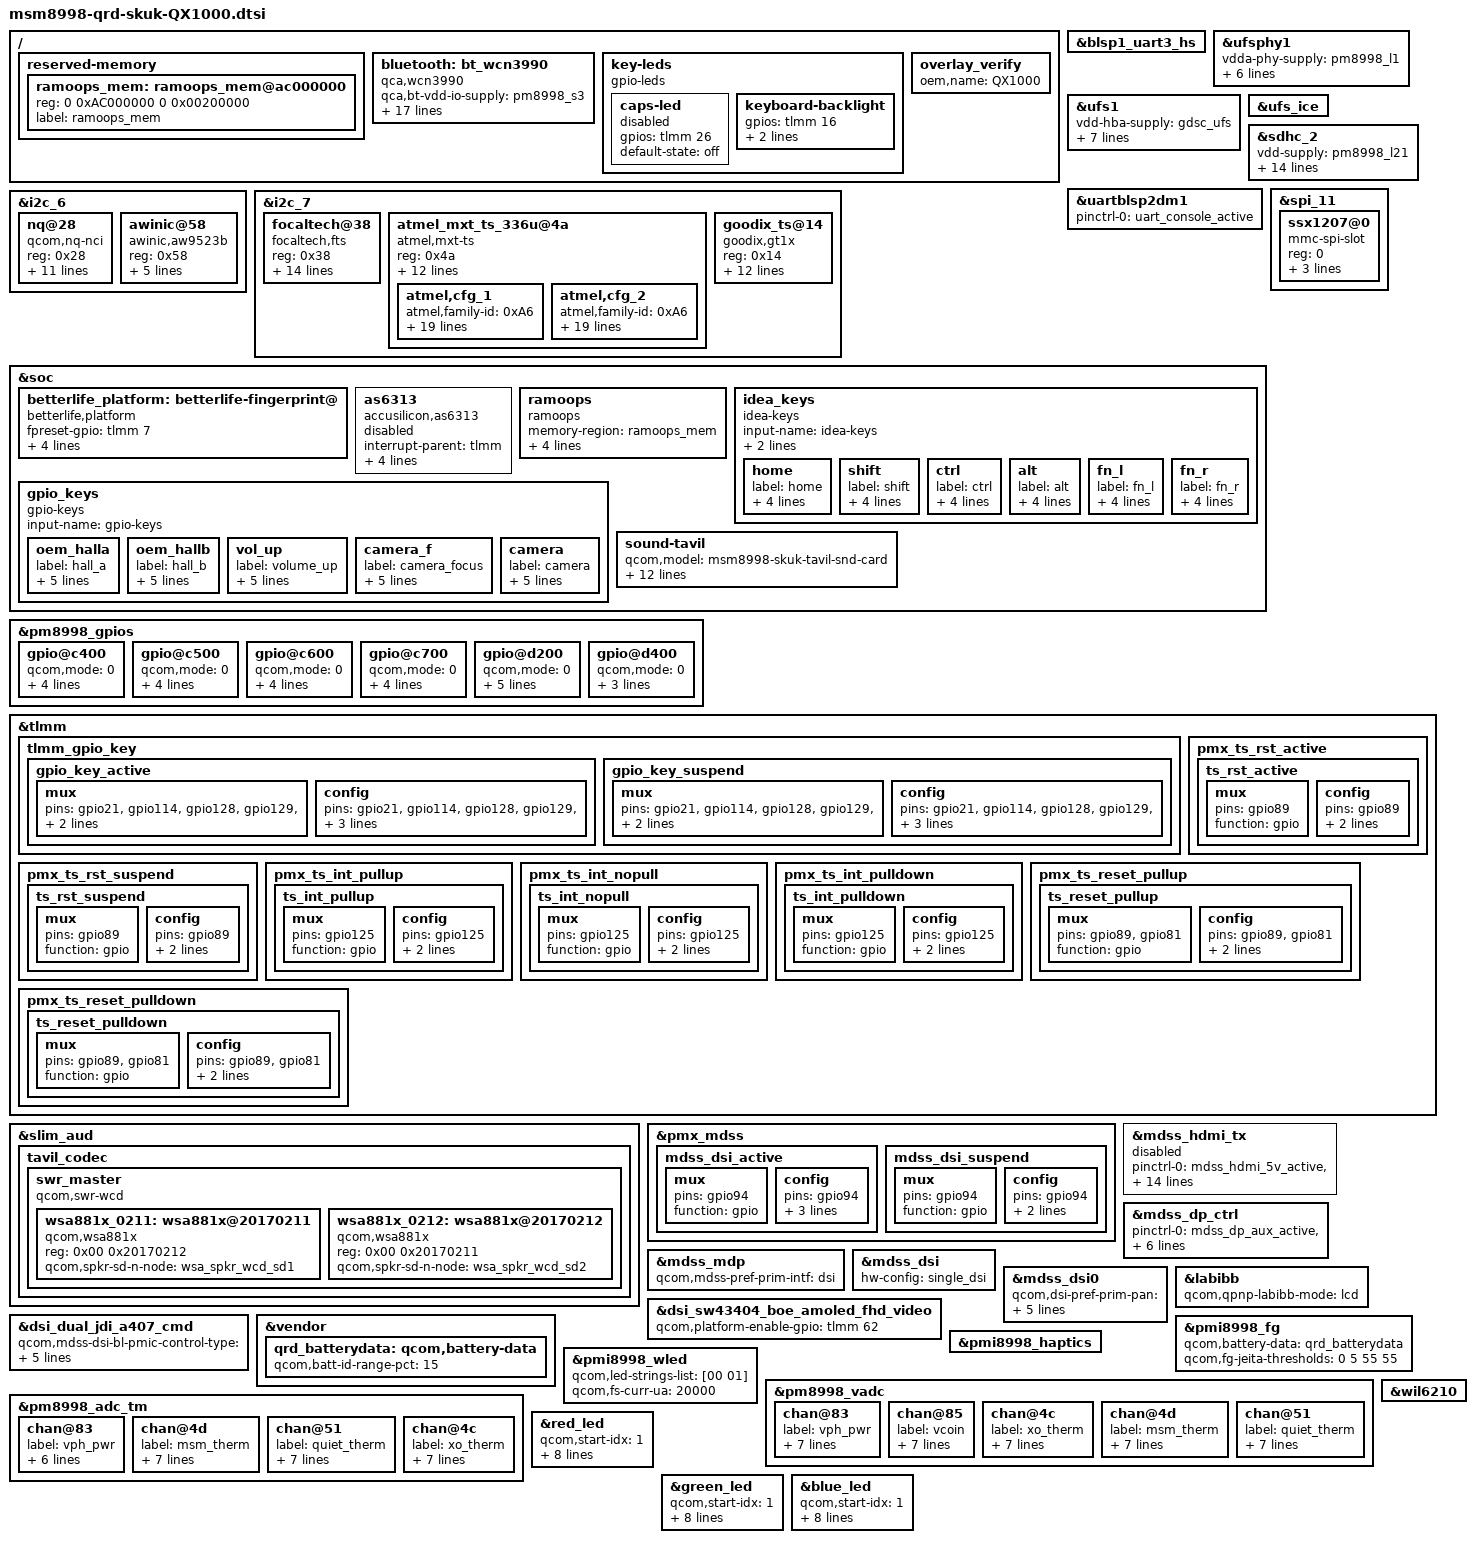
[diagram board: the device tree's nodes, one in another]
/* Copyright (c) 2016-2017, The Linux Foundation. All rights reserved.
 *
 * This program is free software; you can redistribute it and/or modify
 * it under the terms of the GNU General Public License version 2 and
 * only version 2 as published by the Free Software Foundation.
 *
 * This program is distributed in the hope that it will be useful,
 * but WITHOUT ANY WARRANTY; without even the implied warranty of
 * MERCHANTABILITY or FITNESS FOR A PARTICULAR PURPOSE.  See the
 * GNU General Public License for more details.
 */

#include <dt-bindings/interrupt-controller/irq.h>
#include "msm8998-pinctrl.dtsi"
#include "msm8998-audio.dtsi"

/ {
	reserved-memory {
		ramoops_mem: ramoops_mem@ac000000 {
			reg = <0 0xAC000000 0 0x00200000>;
			label = "ramoops_mem";
		};
	};
};

/ {
	bluetooth: bt_wcn3990 {
		compatible = "qca,wcn3990";
		qca,bt-vdd-io-supply = <&pm8998_s3>;
		qca,bt-vdd-xtal-supply = <&pm8998_s5>;
		qca,bt-vdd-core-supply = <&pm8998_l7>;
		qca,bt-vdd-pa-supply = <&pm8998_l17>;
		qca,bt-vdd-ldo-supply = <&pm8998_l25>;
		qca,bt-chip-pwd-supply = <&pmi8998_bob_pin1>;
		clocks = <&clock_gcc clk_rf_clk2_pin>;
		clock-names = "rf_clk2";

		qca,bt-vdd-io-voltage-level = <1352000 1352000>;
		qca,bt-vdd-xtal-voltage-level = <2040000 2040000>;
		qca,bt-vdd-core-voltage-level = <1800000 1800000>;
		qca,bt-vdd-pa-voltage-level = <1304000 1304000>;
		qca,bt-vdd-ldo-voltage-level = <3312000 3312000>;
		qca,bt-chip-pwd-voltage-level = <3600000 3600000>;

		qca,bt-vdd-io-current-level = <1>; /* LPM/PFM */
		qca,bt-vdd-xtal-current-level = <1>; /* LPM/PFM */
		qca,bt-vdd-core-current-level = <1>; /* LPM/PFM */
		qca,bt-vdd-pa-current-level = <1>; /* LPM/PFM */
		qca,bt-vdd-ldo-current-level = <1>; /* LPM/PFM */
	};

	key-leds{
		compatible = "gpio-leds";
		caps-led {
			gpios = <&tlmm 26 0x00>;
			default-state = "off";
			status = "disable";

		};
		keyboard-backlight {
			gpios = <&tlmm 16 0x00>;
			default-state = "off";
			retain-state-suspended;
		};
	};
};

&blsp1_uart3_hs {
	status = "ok";
};

&ufsphy1 {
	vdda-phy-supply = <&pm8998_l1>;
	vdda-pll-supply = <&pm8998_l2>;
	vddp-ref-clk-supply = <&pm8998_l26>;
	vdda-phy-max-microamp = <51400>;
	vdda-pll-max-microamp = <14600>;
	vddp-ref-clk-max-microamp = <100>;
	vddp-ref-clk-always-on;
	status = "ok";
};

&ufs1 {
	vdd-hba-supply = <&gdsc_ufs>;
	vdd-hba-fixed-regulator;
	vcc-supply = <&pm8998_l20>;
	vccq-supply = <&pm8998_l26>;
	vccq2-supply = <&pm8998_s4>;
	vcc-max-microamp = <750000>;
	vccq-max-microamp = <560000>;
	vccq2-max-microamp = <750000>;
	status = "ok";
};

&ufs_ice {
	status = "ok";
};

&sdhc_2 {
	vdd-supply = <&pm8998_l21>;
	qcom,vdd-voltage-level = <2950000 2960000>;
	qcom,vdd-current-level = <200 800000>;

	vdd-io-supply = <&pm8998_l13>;
	qcom,vdd-io-voltage-level = <1808000 2960000>;
	qcom,vdd-io-current-level = <200 22000>;

	pinctrl-names = "active", "sleep";
	pinctrl-0 = <&sdc2_clk_on  &sdc2_cmd_on &sdc2_data_on &sdc2_cd_on>;
	pinctrl-1 = <&sdc2_clk_off &sdc2_cmd_off &sdc2_data_off &sdc2_cd_off>;

	qcom,clk-rates = <400000 20000000 25000000
				50000000 100000000 200000000>;
	qcom,bus-speed-mode = "SDR12", "SDR25", "SDR50", "DDR50", "SDR104";

	cd-gpios = <&tlmm 95 0x1>;

	status = "ok";
};

&uartblsp2dm1 {
	status = "ok";
	pinctrl-names = "default";
	pinctrl-0 = <&uart_console_active>;
};

&i2c_6 { /* BLSP1 QUP6 (NFC) */
	status = "okay";
	nq@28 {
		compatible = "qcom,nq-nci";
		reg = <0x28>;
		qcom,nq-irq = <&tlmm 92 0x00>;
		qcom,nq-ven = <&tlmm 12 0x00>;
		qcom,nq-firm = <&tlmm 93 0x00>;
		qcom,nq-clkreq = <&pm8998_gpios 21 0x00>;
		qcom,nq-esepwr = <&tlmm 116 0x00>;
		interrupt-parent = <&tlmm>;
		qcom,clk-src = "BBCLK3";
		interrupts = <92 0>;
		interrupt-names = "nfc_irq";
		pinctrl-names = "nfc_active", "nfc_suspend";
		pinctrl-0 = <&nfc_int_active &nfc_enable_active>;
		pinctrl-1 = <&nfc_int_suspend &nfc_enable_suspend>;
		clocks = <&clock_gcc clk_ln_bb_clk3_pin>;
		clock-names = "ref_clk";
	};

	awinic@58 {
		compatible = "awinic,aw9523b";
		reg = <0x58>;
		interrupt-parent = <&tlmm>;
		interrupts = <50 0x2008>;
		interrupt-names = "kpd_irq";
		awinic,reset-gpio = <&tlmm 51 0>;
		awinic,caps-gpio = <&tlmm 26 0>;
		awinic,irq-gpio = <&tlmm 50 0x2008>;
	};
};
&i2c_7 {
	status = "okay";
	focaltech@38{
		compatible = "focaltech,fts";
		reg = <0x38>;
		interrupt-parent = <&tlmm>;
		interrupts = <125 0x2008>;
		focaltech,reset-gpio = <&tlmm 89 0x00>;
		ysensor-supply = <&pm8998_l21>;
		//focaltech,power-gpio = <&tlmm 77 0x00>;
		focaltech,irq-gpio = <&tlmm 125 0x2008>;
		focaltech,max-touch-number = <5>;
		focaltech,display-coords =  <0 0 1080 2160>;

		//pinctrl-names = "pmx_ts_active","pmx_ts_suspend","pmx_ts_release";
		//pinctrl-0 = <&ts_int_active &ts_reset_active>;
		//pinctrl-1 = <&ts_int_suspend &ts_reset_suspend>;
		//pinctrl-2 = <&ts_release>;

		vcc_i2c-supply = <&pm8998_l6>;
		vdd-supply = <&pm8998_l28>;
		focaltech,have-key;
		focaltech,key-number = <3>;
		focaltech,keys = <139 102 158>;
		focaltech,key-y-coord = <2000>;
		focaltech,key-x-coords = <200 600 800>;
	};
	atmel_mxt_ts_336u@4a {
                   compatible = "atmel,mxt-ts";
                   reg = <0x4a>;
                   interrupt-parent = <&tlmm>;
                   interrupts = <125 0x2008>;
                   vddio-supply = <&pm8998_l6>;
                   vdd-supply = <&pm8998_l28>;
                   /* pins used by touchscreen */
                   //pinctrl-names = "pmx_ts_active","pmx_ts_suspend";
                   //pinctrl-0 = <&ts_int_active &ts_reset_active>;
                   //pinctrl-1 = <&ts_int_suspend &ts_reset_suspend>;
                   atmel,reset-gpio = <&tlmm 89 0x00>;
                   atmel,irq-gpio = <&tlmm 125 0x2008>;
                   atmel,mxt-fw-name = "mXT336U10AA.fw";
                   atmel,config-array-size = <2>;
                   atmel,default-config = <0>;
                   atmel,irqflags = <0x2008>;
                   atmel,vendor-id-byte = /bits/ 8 <0 3>;
                   atmel,cut-off-power = <1>;
                   atmel,cfg_1 {
                            atmel,family-id = <0xA6>;
                            atmel,variant-id = <0x06>;
                            atmel,version = <0x10>;
                            atmel,build = <0xAA>;
                            atmel,rev-id = <0x2>;
                            atmel,mxt-cfg-name = "mxt_336u_biel_hw1_config.fw";
                            atmel,vendor-id = /bits/ 8 <0x31 0x31>; /* Biel HW ver 1 */
                            atmel,key-codes = <158 102 139>;
                            atmel,selfintthr-stylus = <0>;
                            atmel,t71-tchthr-pos = <22>;
                            atmel,self-chgtime-min = <0>;
                            atmel,self-chgtime-max = <0>;
                            atmel,mult-intthr-sensitive = <12>;
                            atmel,mult-intthr-not-sensitive = <17>;
                            atmel,atchthr-sensitive = <6>;
                            atmel,mult-tchthr-sensitive = <0>;
                            atmel,mult-tchthr-not-sensitive = <0>;
                            atmel,wake-up-self-adcx = <16>;
                            atmel,support-wakeup-gesture;
                   };
                   atmel,cfg_2 {
                            atmel,family-id = <0xA6>;
                            atmel,variant-id = <0x06>;
                            atmel,version = <0x10>;
                            atmel,build = <0xAA>;
                            atmel,rev-id = <0x2>;
                            atmel,mxt-cfg-name = "mxt_336u_biel_hw2_config.fw";
                            atmel,vendor-id = /bits/ 8 <0x31 0x32>; /* Biel HW ver 2 */
                            atmel,key-codes = <158 102 139>;
                            atmel,selfintthr-stylus = <0>;
                            atmel,t71-tchthr-pos = <22>;
                            atmel,self-chgtime-min = <0>;
                            atmel,self-chgtime-max = <0>;
                            atmel,mult-intthr-sensitive = <12>;
                            atmel,mult-intthr-not-sensitive = <17>;
                            atmel,atchthr-sensitive = <6>;
                            atmel,mult-tchthr-sensitive = <0>;
                            atmel,mult-tchthr-not-sensitive = <0>;
                            atmel,wake-up-self-adcx = <16>;
                            atmel,support-wakeup-gesture;
                   };
         };

		goodix_ts@14 {
			compatible = "goodix,gt1x";
			reg = <0x14>;
			interrupt-parent = <&tlmm>;
			interrupts = <125 0x2008>;
			vdd_ana-supply = <&pm8998_l28>;
			//vcc_i2c-supply = <&pm8998_l6>;
			goodix,rst-gpio = <&tlmm 89 0x00>;
			goodix,pwr-gpio = <&tlmm 81 0x00>;
			goodix,irq-gpio = <&tlmm 125 0x2008>;
			pinctrl-names = "pmx_ts_wakeup","pmx_ts_normal","pmx_ts_poweroff","pmx_ts_sleep";
			pinctrl-0 = <&ts_int_pullup &ts_reset_pullup>;
			pinctrl-1 = <&ts_int_nopull &ts_reset_pullup>;
			pinctrl-2 = <&ts_int_pulldown &ts_reset_pulldown>;
			pinctrl-3 = <&ts_int_pulldown &ts_reset_pullup>;
			
			goodix,default-config0 = [
			46 38 04 70 08 3A 0C 00 01
			60 00 06 50 3C 33 01 00 0C
			00 00 28 17 1A 1D 08 06 00
			00 00 00 41 44 00 00 00 00
			12 14 00 40 00 00 00 00 00
			00 88 28 20 64 66 10 09 00
			00 38 AE 53 24 44 03 2D 96
			C0 94 02 00 18 04 C8 3E 9F
			50 8A 61 7F 73 00 84 00 00
			00 00 00 00 00 00 00 00 00
			00 00 00 00 00 00 00 00 00
			00 00 00 00 00 00 00 33 00
			00 00 00 00 00 00 06 00 00
			00 00 00 00 00 00 20 00 00
			00 00 00 00 00 00 00 00 00
			00 DF 07 32 1E 05 03 04 00
			02 01 07 06 08 09 0B 0A 0C
			0D 0E 0F 10 11 12 13 14 15
			16 17 18 19 1A 1B 1C 1D 1E
			1F 02 01 03 04 05 06 07 08
			09 0B 0F 0C 0E 0D 0A 18 FF
			FF FF FF FF FF 00 30 00 00
			00 0F F0 00 00 80 00 00 00
			00 00 00 00 00 00 00 00 00
			14 88 34 65 78 00 14 50 6D
			91 14 28 00 54 10 00 00 00
			00 00 9E 28 01];

	};	 
};

&spi_11 {//enable gpio is config in file kernel/msm-4.4/drivers/mmc/host/mmc_spi.c
    ssx1207@0 {
    compatible = "mmc-spi-slot";
    reg = <0>;
    spi-max-frequency = <50000000>;
    spi-cpol;
    spi-cpha;
    //spi-cs-high;
    };
};

&soc {

    betterlife_platform: betterlife-fingerprint@ {
        compatible = "betterlife,platform";
        fpreset-gpio = <&tlmm 7 0>;
        fpint-gpio = <&tlmm 126 0>;
        fppower-gpio = <&tlmm 25 0>;
        //fppower-gpio1v8 = <&tlmm 25 0>;
        interrupt-parent = <&tlmm>;
        interrupts = <126 0x0>;
        status = "okay";
    };
 
    as6313 {
        compatible = "accusilicon,as6313";
        //reg = <0x0d>;
        //vdd-sim-supply = <&pm8994_l9>;
        interrupt-parent = <&tlmm>;
        interrupts = <123 0x2008>; //79
        sck-gpio = <&tlmm 32 0x00>;
        sda-gpio = <&tlmm 33 0x00>;
        irq-gpio = <&tlmm 123 0x2008>;
		status = "disable";
    };

    ramoops {
        compatible = "ramoops";
        status = "ok";
        memory-region = <&ramoops_mem>;
        console-size = <0x0 0x00080000>;
        pmsg-size    = <0x0 0x00040000>;
        record-size  = <0x0 0x00008000>;
        ftrace-size  = <0x0 0x00020000>;
    };
};

&pm8998_gpios {
	/* GPIO 5 for Home Key */
	gpio@c400 {
		status = "okay";
		qcom,mode = <0>;
		qcom,pull = <0>;
		qcom,vin-sel = <0>;
		qcom,src-sel = <0>;
		qcom,out-strength = <1>;
	};

	/* GPIO 6 for Vol+ Key */
	gpio@c500 {
		status = "okay";
		qcom,mode = <0>;
		qcom,pull = <0>;
		qcom,vin-sel = <0>;
		qcom,src-sel = <0>;
		qcom,out-strength = <1>;
	};
	gpio@c600 {
		status = "okay";
		qcom,mode = <0>;
		qcom,pull = <0>;
		qcom,vin-sel = <0>;
		qcom,src-sel = <0>;
		qcom,out-strength = <1>;
	};
	gpio@c700 {
		status = "okay";
		qcom,mode = <0>;
		qcom,pull = <0>;
		qcom,vin-sel = <0>;
		qcom,src-sel = <0>;
		qcom,out-strength = <1>;
	};

	gpio@d200 { /* GPIO 19 - wil6210 refclk3_en */
		qcom,mode = <0>;		/* Input */
		qcom,pull = <5>;		/* No Pull */
		qcom,vin-sel = <1>;		/* VIN1 GPIO_MV */
		qcom,src-sel = <0>;		/* GPIO */
		qcom,invert = <0>;		/* Invert */
		qcom,master-en = <1>;		/* Enable GPIO */
		status = "okay";
	};

	/* GPIO 21 (NFC_CLK_REQ) */
	gpio@d400 {
		qcom,mode = <0>;
		qcom,vin-sel = <1>;
		qcom,src-sel = <0>;
		qcom,master-en = <1>;
		status = "okay";
	};
};

&tlmm{
	tlmm_gpio_key {
           gpio_key_active: gpio_key_active {
                 mux {                                                                                                              
                     pins = "gpio21", "gpio114","gpio128","gpio129","gpio32","gpio33";
                     function = "gpio";
                 };
 
                 config {
                     pins = "gpio21", "gpio114","gpio128","gpio129","gpio32","gpio33";
                     drive-strength = <2>;
                     bias-pull-up;
                 };
             };
 
             gpio_key_suspend: gpio_key_suspend {
                 mux {
                     pins = "gpio21", "gpio114","gpio128","gpio129","gpio32","gpio33";
                     function = "gpio";
                 };
 
                 config {
                     pins = "gpio21", "gpio114","gpio128","gpio129","gpio32","gpio33";
                     drive-strength = <2>;
                     bias-pull-up;
                 };
             };
    };
};

&soc {

	idea_keys {
		compatible = "idea-keys";
		input-name = "idea-keys";
		pinctrl-names = "idea_gpio_key_active", "idea_gpio_key_suspend";
		pinctrl-0 = <&gpio_key_active>;
		pinctrl-1 = <&gpio_key_suspend>;

		home {
			label = "home";
			gpios = <&tlmm 21 0x1>;
			linux,input-type = <1>;
			linux,code = <125>;
			debounce-interval = <15>;
		};

		shift {
			label = "shift";
			gpios = <&tlmm 114 0x1>;
			linux,input-type = <1>;
			linux,code = <54>;
			debounce-interval = <15>;
		};
		
		ctrl {
			label = "ctrl";
			gpios = <&tlmm 128 0x1>;
			linux,input-type = <1>;
			linux,code = <29>;
			debounce-interval = <15>;
		};

		alt {
			label = "alt";
			gpios = <&tlmm 129 0x1>;
			linux,input-type = <1>;
			linux,code = <56>;
			debounce-interval = <15>;
		};

		fn_l {
			label = "fn_l";
			gpios = <&tlmm 33 0x1>;
			linux,input-type = <1>;
			linux,code = <464>;
			debounce-interval = <15>;
		};

		fn_r {
			label = "fn_r";
			gpios = <&tlmm 32 0x1>;
			linux,input-type = <1>;
			linux,code = <464>;
			debounce-interval = <15>;
		};
	};

	gpio_keys {
		compatible = "gpio-keys";
		input-name = "gpio-keys";
		status = "okay";
		
		oem_halla {
			label = "hall_a";
			gpios = <&tlmm 82 0x1>;
			linux,input-type = <1>;
			linux,code = <468>;
			gpio-key,wakeup;
			debounce-interval = <15>;
		};

		oem_hallb {
			label = "hall_b";
			gpios = <&tlmm 124 0x1>;
			linux,input-type = <1>;
			linux,code = <470>;
			gpio-key,wakeup;
			debounce-interval = <15>;
		};

		vol_up {
			label = "volume_up";
			gpios = <&pm8998_gpios 6 0x1>;
			linux,input-type = <1>;
			linux,code = <115>;
			gpio-key,wakeup;
			debounce-interval = <15>;
		};
		camera_f {
			label = "camera_focus";
			gpios = <&pm8998_gpios 8 0x1>;
			linux,input-type = <1>;
			linux,code = <528>;
			gpio-key,wakeup;
			debounce-interval = <15>;
		};

		camera {
			label = "camera";
			gpios = <&pm8998_gpios 7 0x1>;
			linux,input-type = <1>;
			linux,code = <212>;
			gpio-key,wakeup;
			debounce-interval = <15>;
		};

	};	

	sound-tavil {
		qcom,model = "msm8998-skuk-tavil-snd-card";

		qcom,audio-routing =
			"AIF4 VI", "MCLK",
			"RX_BIAS", "MCLK",
			"AMIC2", "MIC BIAS2",
			"MIC BIAS2", "Headset Mic",
			"DMIC0", "MIC BIAS1",
			"MIC BIAS1", "Digital Mic0",
			"DMIC1", "MIC BIAS1",
			"MIC BIAS1", "Digital Mic1",
			"DMIC2", "MIC BIAS3",
			"MIC BIAS3", "Digital Mic2",
			"DMIC4", "MIC BIAS4",
			"MIC BIAS4", "Digital Mic4",
			"SpkrLeft IN", "SPK1 OUT",
			"SpkrRight IN", "SPK2 OUT";

		qcom,msm-mbhc-hphl-swh = <1>;

		qcom,wsa-max-devs = <2>;
		qcom,wsa-devs = <&wsa881x_0211>, <&wsa881x_0212>;
		qcom,wsa-aux-dev-prefix = "SpkrLeft", "SpkrRight";
	};
/*
	hbtp {
		compatible = "qcom,hbtp-input";
		pinctrl-names = "pmx_ts_active","pmx_ts_suspend";
		pinctrl-0 = <&ts_rst_active>;
		pinctrl-1 = <&ts_rst_suspend>;
		vcc_ana-supply = <&pm8998_l28>;
		vcc_dig-supply = <&pm8998_l6>;
		qcom,afe-load = <20000>;
		qcom,afe-vtg-min = <3008000>;
		qcom,afe-vtg-max = <3008000>;
		qcom,dig-load = <40000>;
		qcom,dig-vtg-min = <1808000>;
		qcom,dig-vtg-max = <1808000>;
		qcom,fb-resume-delay-us = <10000>;
		qcom,afe-power-on-delay-us = <1000>;
		qcom,afe-power-off-delay-us = <6>;
	};
*/
};
&slim_aud {
	tavil_codec {
		swr_master {
			compatible = "qcom,swr-wcd";
			#address-cells = <2>;
			#size-cells = <0>;

			wsa881x_0211: wsa881x@20170211 {
				compatible = "qcom,wsa881x";
				reg = <0x00 0x20170212>;
				qcom,spkr-sd-n-node = <&wsa_spkr_wcd_sd1>;
			};

			wsa881x_0212: wsa881x@20170212 {
				compatible = "qcom,wsa881x";
				reg = <0x00 0x20170211>;
				qcom,spkr-sd-n-node = <&wsa_spkr_wcd_sd2>;
			};
		};
	};
};

&pmx_mdss {
	mdss_dsi_active: mdss_dsi_active {
		mux {
			pins = "gpio94";
			function = "gpio";
		};

		config {
			pins = "gpio94";
			drive-strength = <8>; /* 8 mA */
			bias-disable = <0>; /* no pull */
			output-high;
		};
	};

	mdss_dsi_suspend: mdss_dsi_suspend {
		mux {
			pins = "gpio94";
			function = "gpio";
		};

		config {
			pins = "gpio94";
			drive-strength = <2>; /* 2 mA */
			bias-pull-down; /* pull down */
		};
	};
};

&mdss_hdmi_tx {
	pinctrl-names = "hdmi_hpd_active", "hdmi_ddc_active", "hdmi_cec_active",
				"hdmi_active", "hdmi_sleep";
	pinctrl-0 = <&mdss_hdmi_5v_active  &mdss_hdmi_hpd_active
			&mdss_hdmi_ddc_suspend &mdss_hdmi_cec_suspend>;
	pinctrl-1 = <&mdss_hdmi_5v_active &mdss_hdmi_hpd_active
			&mdss_hdmi_ddc_active &mdss_hdmi_cec_suspend>;
	pinctrl-2 = <&mdss_hdmi_5v_active &mdss_hdmi_hpd_active
			&mdss_hdmi_cec_active &mdss_hdmi_ddc_suspend>;
	pinctrl-3 = <&mdss_hdmi_5v_active &mdss_hdmi_hpd_active
			&mdss_hdmi_ddc_active &mdss_hdmi_cec_active>;
	pinctrl-4 = <&mdss_hdmi_5v_suspend &mdss_hdmi_hpd_suspend
			&mdss_hdmi_ddc_suspend &mdss_hdmi_cec_suspend>;
	status = "disable";
};

&mdss_dp_ctrl {
	pinctrl-names = "mdss_dp_active", "mdss_dp_sleep";
	pinctrl-0 = <&mdss_dp_aux_active &mdss_dp_usbplug_cc_active>;
	pinctrl-1 = <&mdss_dp_aux_suspend &mdss_dp_usbplug_cc_suspend>;
	qcom,aux-en-gpio = <&tlmm 77 0>;
	qcom,aux-sel-gpio = <&tlmm 78 0>;
	qcom,usbplug-cc-gpio = <&tlmm 38 0>;
};


&mdss_mdp {
	qcom,mdss-pref-prim-intf = "dsi";
};

&mdss_dsi {
	hw-config = "single_dsi";
};

&mdss_dsi0 {
	qcom,dsi-pref-prim-pan = <&dsi_sw43404_boe_amoled_fhd_video>;
	pinctrl-names = "mdss_default", "mdss_sleep";
	pinctrl-0 = <&mdss_dsi_active &mdss_te_active>;
	pinctrl-1 = <&mdss_dsi_suspend &mdss_te_suspend>;
	qcom,platform-reset-gpio = <&tlmm 94 0>;
	qcom,platform-te-gpio = <&tlmm 10 0>;
};

/*
&mdss_dsi1 {
	qcom,dsi-pref-prim-pan = <&dsi_dual_jdi_a407_cmd>;
	pinctrl-names = "mdss_default", "mdss_sleep";
	pinctrl-0 = <&mdss_dsi_active &mdss_te_active>;
	pinctrl-1 = <&mdss_dsi_suspend &mdss_te_suspend>;
	qcom,platform-reset-gpio = <&tlmm 94 0>;
	qcom,platform-te-gpio = <&tlmm 10 0>;
};
*/

&labibb {
	status = "ok";
	qcom,qpnp-labibb-mode = "lcd";
};

&dsi_sw43404_boe_amoled_fhd_video{
	 qcom,platform-enable-gpio = <&tlmm 62 0>;
	//qcom,platform-avdd-en-gpio = <&tlmm 62 0>;
};

&dsi_dual_jdi_a407_cmd {
	qcom,mdss-dsi-bl-pmic-control-type = "bl_ctrl_wled";
	qcom,mdss-dsi-bl-min-level = <1>;
	qcom,mdss-dsi-bl-max-level = <4095>;
	qcom,panel-supply-entries = <&dsi_panel_pwr_supply>;
};

&vendor {
	qrd_batterydata: qcom,battery-data {
		qcom,batt-id-range-pct = <15>;
		#include "t5-1-batterydata-qrd-skuk-3150mah.dtsi"
		//#include "fg-gen3-batterydata-qrd-skuk-4v4-3000mah.dtsi"
	};
};

&pmi8998_fg {
	qcom,battery-data = <&qrd_batterydata>;
	qcom,fg-jeita-thresholds = <0 5 55 55>;
};

&pmi8998_haptics {
	status = "okay";
};

&pmi8998_wled {
	qcom,led-strings-list = [00 01];
	qcom,fs-curr-ua = <20000>;
};

&tlmm {
	/* add pingrp for touchscreen */
	pmx_ts_rst_active {
		ts_rst_active: ts_rst_active {
			mux {
				pins = "gpio89";
				function = "gpio";
			};

			config {
				pins = "gpio89";
				drive-strength = <16>;
				bias-pull-up;
			};
		};
	};

	pmx_ts_rst_suspend {
		ts_rst_suspend: ts_rst_suspend {
			mux {
				pins = "gpio89";
				function = "gpio";
			};

			config {
				pins = "gpio89";
				drive-strength = <2>;
				bias-pull-down;
			};
		};
	};
	pmx_ts_int_pullup {
		ts_int_pullup: ts_int_pullup {
			mux {
				pins = "gpio125";
				function = "gpio";
			};

			config {
				pins = "gpio125";
				drive-strength = <8>;
				bias-pull-up;
			};
		};
	};

	pmx_ts_int_nopull {
		ts_int_nopull: ts_int_nopull {
			mux {
				pins = "gpio125";
				function = "gpio";
			};

			config {
				pins = "gpio125";
				drive-strength = <2>;
				bias-disable;
			};
		};
	};

	pmx_ts_int_pulldown {
		ts_int_pulldown: ts_int_pulldown {
			mux {
				pins = "gpio125";
				function = "gpio";
			};

			config {
				pins = "gpio125";
				drive-strength = <2>;
				bias-pull-down;
			};
		};
	};

	pmx_ts_reset_pullup {
		ts_reset_pullup: ts_reset_pullup {
			mux {
				pins = "gpio89","gpio81";
				function = "gpio";
			};

			config {
				pins = "gpio89","gpio81";
				drive-strength = <8>;
				output-high;
			};
		};
	};

	pmx_ts_reset_pulldown {
		ts_reset_pulldown: ts_reset_pulldown {
			mux {
				pins = "gpio89","gpio81";
				function = "gpio";
			};

			config {
				pins = "gpio89","gpio81";
				drive-strength = <2>;
				output-low;
			};
		};
	};
};

&pm8998_vadc {
	chan@83 {
		label = "vph_pwr";
		reg = <0x83>;
		qcom,decimation = <2>;
		qcom,pre-div-channel-scaling = <1>;
		qcom,calibration-type = "absolute";
		qcom,scale-function = <0>;
		qcom,hw-settle-time = <0>;
		qcom,fast-avg-setup = <0>;
	};

	chan@85 {
		label = "vcoin";
		reg = <0x85>;
		qcom,decimation = <2>;
		qcom,pre-div-channel-scaling = <1>;
		qcom,calibration-type = "absolute";
		qcom,scale-function = <0>;
		qcom,hw-settle-time = <0>;
		qcom,fast-avg-setup = <0>;
	};

	chan@4c {
		label = "xo_therm";
		reg = <0x4c>;
		qcom,decimation = <2>;
		qcom,pre-div-channel-scaling = <0>;
		qcom,calibration-type = "ratiometric";
		qcom,scale-function = <4>;
		qcom,hw-settle-time = <2>;
		qcom,fast-avg-setup = <0>;
	};

	chan@4d {
		label = "msm_therm";
		reg = <0x4d>;
		qcom,decimation = <2>;
		qcom,pre-div-channel-scaling = <0>;
		qcom,calibration-type = "ratiometric";
		qcom,scale-function = <2>;
		qcom,hw-settle-time = <2>;
		qcom,fast-avg-setup = <0>;
	};

	chan@51 {
		label = "quiet_therm";
		reg = <0x51>;
		qcom,decimation = <2>;
		qcom,pre-div-channel-scaling = <0>;
		qcom,calibration-type = "ratiometric";
		qcom,scale-function = <2>;
		qcom,hw-settle-time = <2>;
		qcom,fast-avg-setup = <0>;
	};
};

&pm8998_adc_tm {
	chan@83 {
		label = "vph_pwr";
		reg = <0x83>;
		qcom,pre-div-channel-scaling = <1>;
		qcom,calibration-type = "absolute";
		qcom,scale-function = <0>;
		qcom,hw-settle-time = <0>;
		qcom,btm-channel-number = <0x60>;
	};

	chan@4d {
		label = "msm_therm";
		reg = <0x4d>;
		qcom,pre-div-channel-scaling = <0>;
		qcom,calibration-type = "ratiometric";
		qcom,scale-function = <2>;
		qcom,hw-settle-time = <2>;
		qcom,btm-channel-number = <0x68>;
		qcom,thermal-node;
	};

	chan@51 {
		label = "quiet_therm";
		reg = <0x51>;
		qcom,pre-div-channel-scaling = <0>;
		qcom,calibration-type = "ratiometric";
		qcom,scale-function = <2>;
		qcom,hw-settle-time = <2>;
		qcom,btm-channel-number = <0x70>;
		qcom,thermal-node;
	};

	chan@4c {
		label = "xo_therm";
		reg = <0x4c>;
		qcom,pre-div-channel-scaling = <0>;
		qcom,calibration-type = "ratiometric";
		qcom,scale-function = <4>;
		qcom,hw-settle-time = <2>;
		qcom,btm-channel-number = <0x78>;
		qcom,thermal-node;
	};
};

&red_led {
	/delete-property/ linux,default-trigger;
	qcom,start-idx = <1>;
	qcom,idx-len = <10>;
	qcom,duty-pcts = [00 19 32 4b 64
			64 4b 32 19 00];
	qcom,lut-flags = <3>;
	qcom,pause-lo = <0>;
	qcom,pause-hi = <0>;
	qcom,ramp-step-ms = <255>;
	qcom,use-blink;
};

&green_led {
	/delete-property/ linux,default-trigger;
	qcom,start-idx = <1>;
	qcom,idx-len = <10>;
	qcom,duty-pcts = [00 19 32 4b 64
			64 4b 32 19 00];
	qcom,lut-flags = <3>;
	qcom,pause-lo = <0>;
	qcom,pause-hi = <0>;
	qcom,ramp-step-ms = <255>;
	qcom,use-blink;
};

&blue_led {
	/delete-property/ linux,default-trigger;
	qcom,start-idx = <1>;
	qcom,idx-len = <10>;
	qcom,duty-pcts = [00 19 32 4b 64
			64 4b 32 19 00];
	qcom,lut-flags = <3>;
	qcom,pause-lo = <0>;
	qcom,pause-hi = <0>;
	qcom,ramp-step-ms = <255>;
	qcom,use-blink;
};

&wil6210 {
	status = "ok";
};

/{
	overlay_verify:overlay_verify {
		oem,name="QX1000";
	};
};
